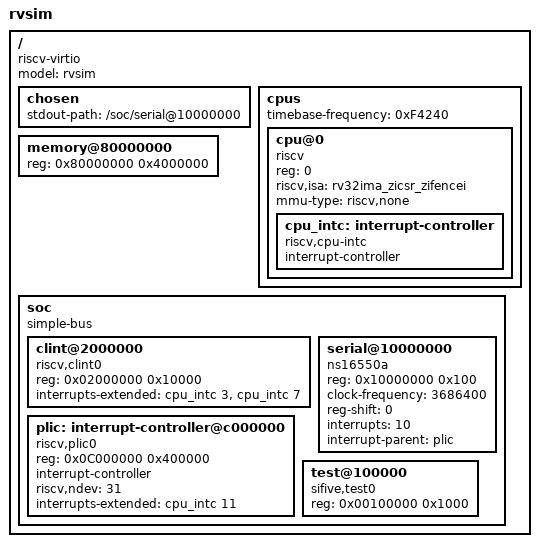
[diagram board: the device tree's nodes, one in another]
/dts-v1/;

/*
 * rvsim 最小设备树
 * 布局与 QEMU virt 对齐（CLINT 0x02000000 / PLIC 0x0C000000 /
 * UART 0x10000000 / syscon 0x00100000 / RAM 0x80000000）
 */
/ {
    #address-cells = <1>;
    #size-cells = <1>;
    compatible = "riscv-virtio";
    model = "rvsim";

    chosen {
        stdout-path = "/soc/serial@10000000";
    };

    cpus {
        #address-cells = <1>;
        #size-cells = <0>;
        timebase-frequency = <0xF4240>;

        cpu@0 {
            device_type = "cpu";
            compatible = "riscv";
            reg = <0>;
            status = "okay";
            riscv,isa = "rv32ima_zicsr_zifencei";
            mmu-type = "riscv,none";

            cpu_intc: interrupt-controller {
                compatible = "riscv,cpu-intc";
                #interrupt-cells = <1>;
                interrupt-controller;
            };
        };
    };

    memory@80000000 {
        device_type = "memory";
        reg = <0x80000000 0x4000000>;
    };

    soc {
        #address-cells = <1>;
        #size-cells = <1>;
        compatible = "simple-bus";
        ranges;

        clint@2000000 {
            compatible = "riscv,clint0";
            reg = <0x02000000 0x10000>;
            interrupts-extended = <&cpu_intc 3 &cpu_intc 7>;
        };

        plic: interrupt-controller@c000000 {
            compatible = "riscv,plic0";
            reg = <0x0C000000 0x400000>;
            #interrupt-cells = <1>;
            interrupt-controller;
            riscv,ndev = <31>;
            interrupts-extended = <&cpu_intc 11>;
        };

        serial@10000000 {
            compatible = "ns16550a";
            reg = <0x10000000 0x100>;
            clock-frequency = <3686400>;
            reg-shift = <0>;
            interrupts = <10>;
            interrupt-parent = <&plic>;
            status = "okay";
        };

        test@100000 {
            compatible = "sifive,test0", "syscon";
            reg = <0x00100000 0x1000>;
        };
    };
};
